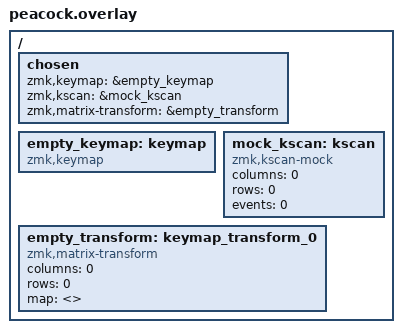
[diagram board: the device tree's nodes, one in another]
#include <behaviors.dtsi>
#include <dt-bindings/zmk/matrix_transform.h>

/ {
    chosen {
        zmk,keymap = &empty_keymap;
        zmk,kscan = &mock_kscan;
        zmk,matrix-transform = &empty_transform;
    };

    empty_keymap: keymap {
        compatible = "zmk,keymap";
    };

    mock_kscan: kscan {
        compatible = "zmk,kscan-mock";
        columns = <0>;
        rows = <0>;
        events = <0>;
    };

    empty_transform: keymap_transform_0 {
        compatible = "zmk,matrix-transform";
        columns = <0>;
        rows = <0>;
        map = <>;
    };
};
